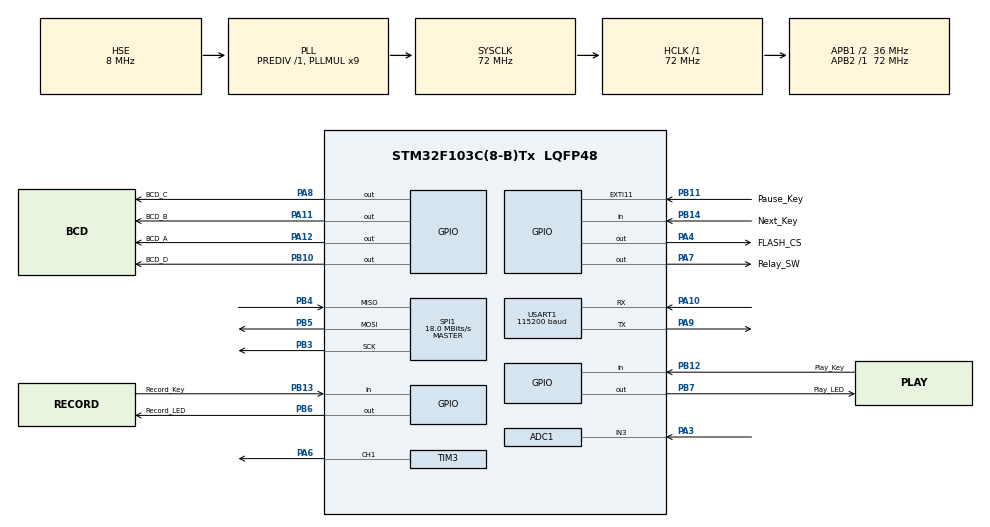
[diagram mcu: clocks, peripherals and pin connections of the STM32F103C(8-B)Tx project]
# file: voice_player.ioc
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ADC1.Channel-2\#ChannelRegularConversion=ADC_CHANNEL_3
ADC1.ContinuousConvMode=ENABLE
ADC1.NbrOfConversionFlag=1
ADC1.Rank-2\#ChannelRegularConversion=1
ADC1.SamplingTime-2\#ChannelRegularConversion=ADC_SAMPLETIME_1CYCLE_5
ADC1.master=1
Mcu.Family=STM32F1
Mcu.Name=STM32F103C(8-B)Tx
Mcu.Package=LQFP48
NVIC.PriorityGroup=NVIC_PRIORITYGROUP_4
NVIC.TIM2_IRQn=true\:0\:0\:false\:false\:true\:true\:true\:true
PA10.Mode=Asynchronous
PA10.Signal=USART1_RX
PA11.GPIO_Label=BCD_B
PA11.GPIO_PuPd=GPIO_PULLDOWN
PA11.Signal=GPIO_Output
PA12.GPIO_Label=BCD_A
PA12.GPIO_PuPd=GPIO_PULLDOWN
PA12.Signal=GPIO_Output
PA13.Mode=Serial_Wire
PA13.Signal=SYS_JTMS-SWDIO
PA14.Mode=Serial_Wire
PA14.Signal=SYS_JTCK-SWCLK
PA3.Signal=ADCx_IN3
PA4.GPIO_Label=FLASH_CS
PA4.GPIO_PuPd=GPIO_PULLUP
PA4.GPIO_Speed=GPIO_SPEED_FREQ_HIGH
PA4.PinState=GPIO_PIN_SET
PA4.Signal=GPIO_Output
PA6.Signal=S_TIM3_CH1
PA7.GPIO_Label=Relay_SW
PA7.GPIO_ModeDefaultOutputPP=GPIO_MODE_OUTPUT_PP
PA7.GPIO_PuPd=GPIO_PULLUP
PA7.Signal=GPIO_Output
PA8.GPIO_Label=BCD_C
PA8.GPIO_PuPd=GPIO_PULLDOWN
PA8.Signal=GPIO_Output
PA9.Mode=Asynchronous
PA9.Signal=USART1_TX
PB10.GPIO_Label=BCD_D
PB10.GPIO_PuPd=GPIO_PULLDOWN
PB10.Signal=GPIO_Output
PB11.GPIO_Label=Pause_Key
PB11.GPIO_ModeDefaultEXTI=GPIO_MODE_EVT_FALLING
PB11.Signal=GPXTI11
PB12.GPIO_Label=Play_Key
PB12.Signal=GPIO_Input
PB13.GPIO_Label=Record_Key
PB13.Signal=GPIO_Input
PB14.GPIO_Label=Next_Key
PB14.Signal=GPIO_Input
PB3.Mode=Full_Duplex_Master
PB3.Signal=SPI1_SCK
PB4.Mode=Full_Duplex_Master
PB4.Signal=SPI1_MISO
PB5.Mode=Full_Duplex_Master
PB5.Signal=SPI1_MOSI
PB6.GPIO_Label=Record_LED
PB6.GPIO_PuPd=GPIO_PULLDOWN
PB6.Signal=GPIO_Output
PB7.GPIO_Label=Play_LED
PB7.GPIO_PuPd=GPIO_PULLDOWN
PB7.Signal=GPIO_Output
PD0-OSC_IN.Mode=HSE-External-Oscillator
PD0-OSC_IN.Signal=RCC_OSC_IN
PD1-OSC_OUT.Mode=HSE-External-Oscillator
PD1-OSC_OUT.Signal=RCC_OSC_OUT
ProjectManager.HeapSize=0x2000
ProjectManager.StackSize=0x4000
ProjectManager.TargetToolchain=STM32CubeIDE
RCC.ADCPresc=RCC_ADCPCLK2_DIV6
RCC.AHBFreq_Value=72000000
RCC.APB1CLKDivider=RCC_HCLK_DIV2
RCC.APB1Freq_Value=36000000
RCC.APB1TimFreq_Value=72000000
RCC.APB2Freq_Value=72000000
RCC.APB2TimFreq_Value=72000000
RCC.HCLKFreq_Value=72000000
RCC.PLLMUL=RCC_PLL_MUL9
RCC.PLLSourceVirtual=RCC_PLLSOURCE_HSE
RCC.SYSCLKFreq_VALUE=72000000
RCC.SYSCLKSource=RCC_SYSCLKSOURCE_PLLCLK
RCC.USBFreq_Value=72000000
SH.ADCx_IN3.0=ADC1_IN3,IN3
SH.S_TIM3_CH1.0=TIM3_CH1,PWM Generation1 CH1
SPI1.BaudRatePrescaler=SPI_BAUDRATEPRESCALER_4
SPI1.CalculateBaudRate=18.0 MBits/s
SPI1.Direction=SPI_DIRECTION_2LINES
SPI1.Mode=SPI_MODE_MASTER
SPI1.VirtualType=VM_MASTER
TIM2.Period=1439
TIM2.Prescaler=1
TIM3.Channel-PWM\ Generation1\ CH1=TIM_CHANNEL_1
TIM3.OCFastMode_PWM-PWM\ Generation1\ CH1=TIM_OCFAST_ENABLE
TIM3.OCMode_PWM-PWM\ Generation1\ CH1=TIM_OCMODE_PWM1
TIM3.Period=1439
TIM3.Prescaler=1
USART1.BaudRate=115200
USART1.Mode=MODE_TX_RX
USART1.VirtualMode=VM_ASYNC
VP_TIM2_VS_ClockSourceINT.Mode=Internal
VP_TIM3_VS_ClockSourceINT.Mode=Internal
board=custom

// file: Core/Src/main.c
/* USER CODE BEGIN Header */
/**
 ******************************************************************************
 * @file           : main.c
 * @brief          : Main program body
 ******************************************************************************
 * @attention
 *
 * Copyright (c) 2023 STMicroelectronics.
 * All rights reserved.
 *
 * This software is licensed under terms that can be found in the LICENSE file
 * in the root directory of this software component.
 * If no LICENSE file comes with this software, it is provided AS-IS.
 *
 ******************************************************************************
 */
/* USER CODE END Header */
#include "main.h"
#include "adc.h"
#include "spi.h"
#include "tim.h"
#include "usart.h"
#include "gpio.h"

/* USER CODE BEGIN Includes */
#include "string.h"
/* USER CODE END Includes */

/* USER CODE BEGIN PTD */
#include "VoiceRecorderInterface.h"
#include "ReadKeyboard.h"
/* USER CODE END PTD */

/* USER CODE BEGIN PM */

void HAL_TIM_PeriodElapsedCallback(TIM_HandleTypeDef *htim);

/* USER CODE END PM */

void SystemClock_Config(void);

int main(void)
{

  /* MCU Configuration--------------------------------------------------------*/

  /* Reset of all peripherals, Initializes the Flash interface and the Systick. */
  HAL_Init();

  /* Configure the system clock */
  SystemClock_Config();

  /* Initialize all configured peripherals */
  MX_GPIO_Init();
  MX_ADC1_Init();
  MX_TIM2_Init();
  MX_TIM3_Init();
  MX_SPI1_Init();
  MX_USART1_UART_Init();

  /* Infinite loop */
  while (1)
  {

    /* USER CODE BEGIN 3 */
    VoiceRecorder();
  }
  /* USER CODE END 3 */
}

void SystemClock_Config(void)
{
  RCC_OscInitTypeDef RCC_OscInitStruct = {0};
  RCC_ClkInitTypeDef RCC_ClkInitStruct = {0};
  RCC_PeriphCLKInitTypeDef PeriphClkInit = {0};

  /** Initializes the RCC Oscillators according to the specified parameters
  * in the RCC_OscInitTypeDef structure.
  */
  RCC_OscInitStruct.OscillatorType = RCC_OSCILLATORTYPE_HSE;
  RCC_OscInitStruct.HSEState = RCC_HSE_ON;
  RCC_OscInitStruct.HSEPredivValue = RCC_HSE_PREDIV_DIV1;
  RCC_OscInitStruct.HSIState = RCC_HSI_ON;
  RCC_OscInitStruct.PLL.PLLState = RCC_PLL_ON;
  RCC_OscInitStruct.PLL.PLLSource = RCC_PLLSOURCE_HSE;
  RCC_OscInitStruct.PLL.PLLMUL = RCC_PLL_MUL9;
  if (HAL_RCC_OscConfig(&RCC_OscInitStruct) != HAL_OK)
  {
    Error_Handler();
  }

  /** Initializes the CPU, AHB and APB buses clocks
  */
  RCC_ClkInitStruct.ClockType = RCC_CLOCKTYPE_HCLK|RCC_CLOCKTYPE_SYSCLK
                              |RCC_CLOCKTYPE_PCLK1|RCC_CLOCKTYPE_PCLK2;
  RCC_ClkInitStruct.SYSCLKSource = RCC_SYSCLKSOURCE_PLLCLK;
  RCC_ClkInitStruct.AHBCLKDivider = RCC_SYSCLK_DIV1;
  RCC_ClkInitStruct.APB1CLKDivider = RCC_HCLK_DIV2;
  RCC_ClkInitStruct.APB2CLKDivider = RCC_HCLK_DIV1;

  if (HAL_RCC_ClockConfig(&RCC_ClkInitStruct, FLASH_LATENCY_2) != HAL_OK)
  {
    Error_Handler();
  }
  PeriphClkInit.PeriphClockSelection = RCC_PERIPHCLK_ADC;
  PeriphClkInit.AdcClockSelection = RCC_ADCPCLK2_DIV6;
  if (HAL_RCCEx_PeriphCLKConfig(&PeriphClkInit) != HAL_OK)
  {
    Error_Handler();
  }
}

/* USER CODE BEGIN 4 */
void HAL_GPIO_EXTI_Callback(uint16_t GPIO_Pin)
{
  //  ReadKeyBoard(GPIO_Pin);
  PauseKey(GPIO_Pin);
}

void HAL_TIM_PeriodElapsedCallback(TIM_HandleTypeDef *htim)
{
  InterruptFunc();
}
/* USER CODE END 4 */

void Error_Handler(void)
{
  __disable_irq();
  while (1)
  {
  }
}
